# udma register map
Vendor: Texas Instruments
Peripheral module from a debugger description file (folder cc32).
Registers are 32-bit, access not given, no defined reset value unless marked. A register's access mark holds for its fields unless they carry their own. Offsets are as the file gives them; lines under a group give offsets from that group; [hi:lo] are bit positions; {n}, {i} and the like mark numbered series; 'fields as' and 'values as' point back to an identical list; <NAME> marks a mode.

## udma
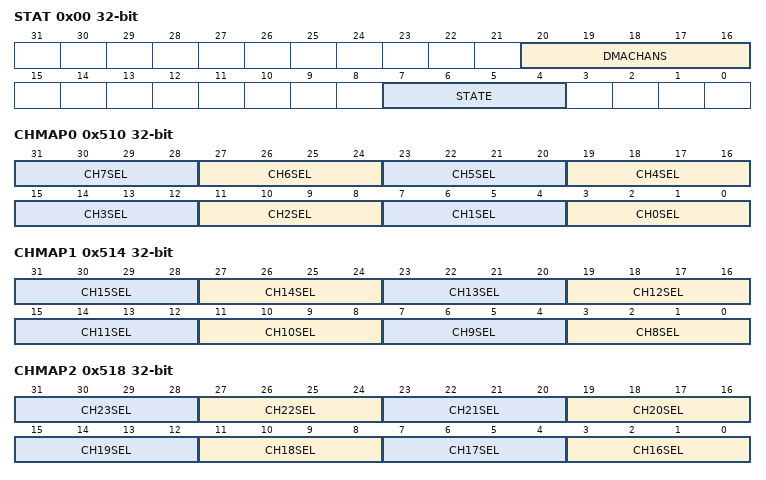
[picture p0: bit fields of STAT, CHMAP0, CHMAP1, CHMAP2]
0x00 STAT rw
  [20:16] DMACHANS — Available uDMA Channels Minus 1
  [7:4] STATE — Control State Machine Status 0x00000090 : UDMA_STAT_STATE_DONE : Done 0x00000000 : UDMA_STAT_STATE_IDLE : Idle 0x00000010 : UDMA_STAT_STATE_RD_CTRL : Reading channel controller data 0x00000030 : UDMA_STAT_STATE_RD_DSTENDP : Reading destination end pointer 0x00000040 : UDMA_STAT_STATE_RD_SRCDAT : Reading source data 0x00000020 : UDMA_STAT_STATE_RD_SRCENDP : Reading source end pointer 0x00000080 : UDMA_STAT_STATE_STALL : Stalled 0x000000A0 : UDMA_STAT_STATE_UNDEF : Undefined 0x00000060 : UDMA_STAT_STATE_WAIT : Waiting for uDMA request to clear 0x00000070 : UDMA_STAT_STATE_WR_CTRL : Writing channel controller data 0x00000050 : UDMA_STAT_STATE_WR_DSTDAT : Writing destination data
0x04 CFG
0x08 CTLBASE rw
  [31:10] ADDR — Channel Control Base Address
0x0C ALTBASE
0x10 WAITSTAT
0x14 SWREQ
0x18 USEBURSTSET
0x1C USEBURSTCLR
0x20 REQMASKSET
0x24 REQMASKCLR
0x28 ENASET
0x2C ENACLR
0x30 ALTSET
0x34 ALTCLR
0x38 PRIOSET
0x3C PRIOCLR
0x4C ERRCLR
0x500 CHASGN
0x504 CHIS
0x510 CHMAP0 rw
  [4n+3:4n] CH{n}SEL (n=0..7) — uDMA Channel {n} Source Select
0x514 CHMAP1 rw
  [4n-29:4n-32] CH{n}SEL (n=8..15) — uDMA Channel {n} Source Select
0x518 CHMAP2 rw
  [4n-61:4n-64] CH{n}SEL (n=16..23) — uDMA Channel {n} Source Select
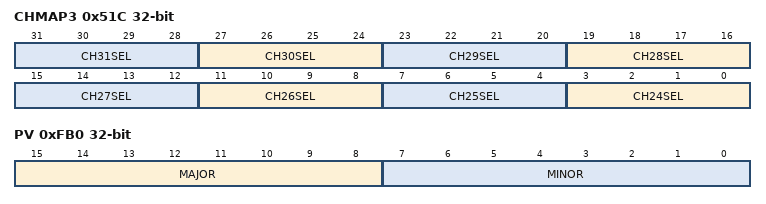
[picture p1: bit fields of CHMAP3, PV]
0x51C CHMAP3 rw
  [4n-93:4n-96] CH{n}SEL (n=24..31) — uDMA Channel {n} Source Select
0xFB0 PV rw
  [15:8] MAJOR — Major Revision
  [7:0] MINOR — Minor Revision
